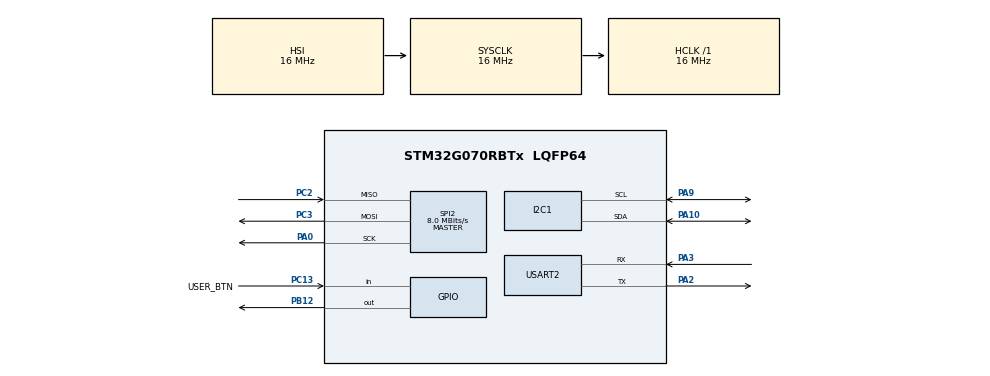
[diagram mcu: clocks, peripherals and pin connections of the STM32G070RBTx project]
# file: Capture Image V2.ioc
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I2C1.Timing=0x00503D58
Mcu.Family=STM32G0
Mcu.Name=STM32G070RBTx
Mcu.Package=LQFP64
PA0.Mode=Full_Duplex_Master
PA0.Signal=SPI2_SCK
PA10.Mode=I2C
PA10.Signal=I2C1_SDA
PA2.Mode=Asynchronous
PA2.Signal=USART2_TX
PA3.Mode=Asynchronous
PA3.Signal=USART2_RX
PA9.Mode=I2C
PA9.Signal=I2C1_SCL
PB12.Signal=GPIO_Output
PC13.GPIO_Label=USER_BTN
PC13.Signal=GPIO_Input
PC2.Mode=Full_Duplex_Master
PC2.Signal=SPI2_MISO
PC3.Mode=Full_Duplex_Master
PC3.Signal=SPI2_MOSI
ProjectManager.HeapSize=0x200
ProjectManager.StackSize=0x400
ProjectManager.TargetToolchain=STM32CubeIDE
RCC.AHBFreq_Value=16000000
RCC.CortexFreq_Value=16000000
RCC.EXTERNAL_CLOCK_VALUE=48000
RCC.HCLKFreq_Value=16000000
RCC.HSE_VALUE=8000000
RCC.HSI_VALUE=16000000
RCC.LSE_VALUE=32768
RCC.SYSCLKFreq_VALUE=16000000
RCC.VCOOutputFreq_Value=128000000
SPI2.CalculateBaudRate=8.0 MBits/s
SPI2.DataSize=SPI_DATASIZE_8BIT
SPI2.Direction=SPI_DIRECTION_2LINES
SPI2.Mode=SPI_MODE_MASTER
SPI2.NSSPMode=SPI_NSS_PULSE_DISABLE
SPI2.VirtualType=VM_MASTER
TIM6.Prescaler=16-1
USART2.VirtualMode-Asynchronous=VM_ASYNC
VP_TIM6_VS_ClockSourceINT.Mode=Enable_Timer
board=custom

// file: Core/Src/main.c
/* USER CODE BEGIN Header */
/**
  ******************************************************************************
  * @file           : main.c
  * @brief          : Main program body
  ******************************************************************************
  * @attention
  *
  * Copyright (c) 2024 STMicroelectronics.
  * All rights reserved.
  *
  * This software is licensed under terms that can be found in the LICENSE file
  * in the root directory of this software component.
  * If no LICENSE file comes with this software, it is provided AS-IS.
  *
  ******************************************************************************
  */
/* USER CODE END Header */
#include "main.h"

/* USER CODE BEGIN Includes */
#include "i2c_func_decl.h"
#include "spi_func_decl.h"
#include <string.h>
/* USER CODE END Includes */

I2C_HandleTypeDef hi2c1;

SPI_HandleTypeDef hspi2;

TIM_HandleTypeDef htim6;

UART_HandleTypeDef huart2;

void SystemClock_Config(void);
static void MX_GPIO_Init(void);
static void MX_I2C1_Init(void);
static void MX_SPI2_Init(void);
static void MX_TIM6_Init(void);
static void MX_USART2_UART_Init(void);
/* USER CODE BEGIN PFP */
void send_status(int status_num);
/* USER CODE END PFP */

int main(void)
{

  /* MCU Configuration--------------------------------------------------------*/

  /* Reset of all peripherals, Initializes the Flash interface and the Systick. */
  HAL_Init();

  /* Configure the system clock */
  SystemClock_Config();

  /* Initialize all configured peripherals */
  MX_GPIO_Init();
  MX_I2C1_Init();
  MX_SPI2_Init();
  MX_TIM6_Init();
  MX_USART2_UART_Init();
  /* USER CODE BEGIN 2 */
  HAL_TIM_Base_Start(&htim6);
  /* USER CODE END 2 */

  /* Infinite loop */
  /* USER CODE BEGIN WHILE */
  //while(!check_cami2c());
  //check if the spi is working
  //while(!check_camspi());
  i2c_config();
  while (1)
  {
    /* USER CODE END WHILE */

    /* USER CODE BEGIN 3 */
	  if(!HAL_GPIO_ReadPin(GPIOC,GPIO_PIN_13))
		  ov2640_capture();
  }
  /* USER CODE END 3 */
}

void SystemClock_Config(void)
{
  RCC_OscInitTypeDef RCC_OscInitStruct = {0};
  RCC_ClkInitTypeDef RCC_ClkInitStruct = {0};

  /** Configure the main internal regulator output voltage
  */
  HAL_PWREx_ControlVoltageScaling(PWR_REGULATOR_VOLTAGE_SCALE1);

  /** Initializes the RCC Oscillators according to the specified parameters
  * in the RCC_OscInitTypeDef structure.
  */
  RCC_OscInitStruct.OscillatorType = RCC_OSCILLATORTYPE_HSI;
  RCC_OscInitStruct.HSIState = RCC_HSI_ON;
  RCC_OscInitStruct.HSIDiv = RCC_HSI_DIV1;
  RCC_OscInitStruct.HSICalibrationValue = RCC_HSICALIBRATION_DEFAULT;
  RCC_OscInitStruct.PLL.PLLState = RCC_PLL_NONE;
  if (HAL_RCC_OscConfig(&RCC_OscInitStruct) != HAL_OK)
  {
    Error_Handler();
  }

  /** Initializes the CPU, AHB and APB buses clocks
  */
  RCC_ClkInitStruct.ClockType = RCC_CLOCKTYPE_HCLK|RCC_CLOCKTYPE_SYSCLK
                              |RCC_CLOCKTYPE_PCLK1;
  RCC_ClkInitStruct.SYSCLKSource = RCC_SYSCLKSOURCE_HSI;
  RCC_ClkInitStruct.AHBCLKDivider = RCC_SYSCLK_DIV1;
  RCC_ClkInitStruct.APB1CLKDivider = RCC_HCLK_DIV1;

  if (HAL_RCC_ClockConfig(&RCC_ClkInitStruct, FLASH_LATENCY_0) != HAL_OK)
  {
    Error_Handler();
  }
}

static void MX_I2C1_Init(void)
{

  hi2c1.Instance = I2C1;
  hi2c1.Init.Timing = 0x00503D58;
  hi2c1.Init.OwnAddress1 = 0;
  hi2c1.Init.AddressingMode = I2C_ADDRESSINGMODE_7BIT;
  hi2c1.Init.DualAddressMode = I2C_DUALADDRESS_DISABLE;
  hi2c1.Init.OwnAddress2 = 0;
  hi2c1.Init.OwnAddress2Masks = I2C_OA2_NOMASK;
  hi2c1.Init.GeneralCallMode = I2C_GENERALCALL_DISABLE;
  hi2c1.Init.NoStretchMode = I2C_NOSTRETCH_DISABLE;
  if (HAL_I2C_Init(&hi2c1) != HAL_OK)
  {
    Error_Handler();
  }

  /** Configure Analogue filter
  */
  if (HAL_I2CEx_ConfigAnalogFilter(&hi2c1, I2C_ANALOGFILTER_ENABLE) != HAL_OK)
  {
    Error_Handler();
  }

  /** Configure Digital filter
  */
  if (HAL_I2CEx_ConfigDigitalFilter(&hi2c1, 0) != HAL_OK)
  {
    Error_Handler();
  }

}

static void MX_SPI2_Init(void)
{

  /* SPI2 parameter configuration*/
  hspi2.Instance = SPI2;
  hspi2.Init.Mode = SPI_MODE_MASTER;
  hspi2.Init.Direction = SPI_DIRECTION_2LINES;
  hspi2.Init.DataSize = SPI_DATASIZE_8BIT;
  hspi2.Init.CLKPolarity = SPI_POLARITY_LOW;
  hspi2.Init.CLKPhase = SPI_PHASE_1EDGE;
  hspi2.Init.NSS = SPI_NSS_SOFT;
  hspi2.Init.BaudRatePrescaler = SPI_BAUDRATEPRESCALER_2;
  hspi2.Init.FirstBit = SPI_FIRSTBIT_MSB;
  hspi2.Init.TIMode = SPI_TIMODE_DISABLE;
  hspi2.Init.CRCCalculation = SPI_CRCCALCULATION_DISABLE;
  hspi2.Init.CRCPolynomial = 7;
  hspi2.Init.CRCLength = SPI_CRC_LENGTH_DATASIZE;
  hspi2.Init.NSSPMode = SPI_NSS_PULSE_DISABLE;
  if (HAL_SPI_Init(&hspi2) != HAL_OK)
  {
    Error_Handler();
  }

}

static void MX_TIM6_Init(void)
{

  TIM_MasterConfigTypeDef sMasterConfig = {0};

  htim6.Instance = TIM6;
  htim6.Init.Prescaler = 16-1;
  htim6.Init.CounterMode = TIM_COUNTERMODE_UP;
  htim6.Init.Period = 65535;
  htim6.Init.AutoReloadPreload = TIM_AUTORELOAD_PRELOAD_DISABLE;
  if (HAL_TIM_Base_Init(&htim6) != HAL_OK)
  {
    Error_Handler();
  }
  sMasterConfig.MasterOutputTrigger = TIM_TRGO_RESET;
  sMasterConfig.MasterSlaveMode = TIM_MASTERSLAVEMODE_DISABLE;
  if (HAL_TIMEx_MasterConfigSynchronization(&htim6, &sMasterConfig) != HAL_OK)
  {
    Error_Handler();
  }

}

static void MX_USART2_UART_Init(void)
{

  huart2.Instance = USART2;
  huart2.Init.BaudRate = 115200;
  huart2.Init.WordLength = UART_WORDLENGTH_8B;
  huart2.Init.StopBits = UART_STOPBITS_1;
  huart2.Init.Parity = UART_PARITY_NONE;
  huart2.Init.Mode = UART_MODE_TX_RX;
  huart2.Init.HwFlowCtl = UART_HWCONTROL_NONE;
  huart2.Init.OverSampling = UART_OVERSAMPLING_16;
  huart2.Init.OneBitSampling = UART_ONE_BIT_SAMPLE_DISABLE;
  huart2.Init.ClockPrescaler = UART_PRESCALER_DIV1;
  huart2.AdvancedInit.AdvFeatureInit = UART_ADVFEATURE_NO_INIT;
  if (HAL_UART_Init(&huart2) != HAL_OK)
  {
    Error_Handler();
  }
  if (HAL_UARTEx_SetTxFifoThreshold(&huart2, UART_TXFIFO_THRESHOLD_1_8) != HAL_OK)
  {
    Error_Handler();
  }
  if (HAL_UARTEx_SetRxFifoThreshold(&huart2, UART_RXFIFO_THRESHOLD_1_8) != HAL_OK)
  {
    Error_Handler();
  }
  if (HAL_UARTEx_DisableFifoMode(&huart2) != HAL_OK)
  {
    Error_Handler();
  }

}

static void MX_GPIO_Init(void)
{
  GPIO_InitTypeDef GPIO_InitStruct = {0};

  /* GPIO Ports Clock Enable */
  __HAL_RCC_GPIOC_CLK_ENABLE();
  __HAL_RCC_GPIOA_CLK_ENABLE();
  __HAL_RCC_GPIOB_CLK_ENABLE();

  /*Configure GPIO pin Output Level */
  HAL_GPIO_WritePin(GPIOB, GPIO_PIN_12, GPIO_PIN_RESET);

  /*Configure GPIO pin : USER_BTN_Pin */
  GPIO_InitStruct.Pin = USER_BTN_Pin;
  GPIO_InitStruct.Mode = GPIO_MODE_INPUT;
  GPIO_InitStruct.Pull = GPIO_NOPULL;
  HAL_GPIO_Init(USER_BTN_GPIO_Port, &GPIO_InitStruct);

  /*Configure GPIO pin : PB12 */
  GPIO_InitStruct.Pin = GPIO_PIN_12;
  GPIO_InitStruct.Mode = GPIO_MODE_OUTPUT_PP;
  GPIO_InitStruct.Pull = GPIO_NOPULL;
  GPIO_InitStruct.Speed = GPIO_SPEED_FREQ_LOW;
  HAL_GPIO_Init(GPIOB, &GPIO_InitStruct);

}

/* USER CODE BEGIN 4 */

void send_status(int status_num){
	//HAL_UART_Transmit_DMA(&huart2,(uint8_t *)strings[status_num],strlen(strings[status_num]));
	HAL_Delay(2000);
}

/* USER CODE END 4 */

void Error_Handler(void)
{
  __disable_irq();
  while (1)
  {
  }
}
